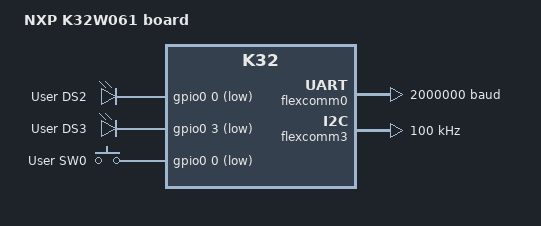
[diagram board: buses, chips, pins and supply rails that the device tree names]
/*
 * Copyright (c) 2021, Vincent van der Locht
 *
 * SPDX-License-Identifier: Apache-2.0
 */

/dts-v1/;

#include <nxp/nxp_k32w061.dtsi>

/ {
	model = "NXP K32W061 board";
	compatible = "nxp,k32w061", "nxp,k32";

	aliases {
		led0 = &red_led_0;
		led1 = &red_led_1;
		sw0 = &user_button;
	};

	chosen {
		zephyr,sram = &sram0;
		zephyr,flash = &flash0;
		zephyr,console = &flexcomm0;
		zephyr,shell-uart = &flexcomm0;
	};

	leds {
		compatible = "gpio-leds";
		red_led_0: led_0 {
			gpios = <&gpio0 0 GPIO_ACTIVE_LOW>;
			label = "User DS2";
		};
		red_led_1: led_1 {
			gpios = <&gpio0 3 GPIO_ACTIVE_LOW>;
			label = "User DS3";
		};
	};

	gpio_keys {
		compatible = "gpio-keys";
		user_button: button_0 {
			label = "User SW0";
			gpios = <&gpio0 0 GPIO_ACTIVE_LOW>;
		};
	};

};

&cpu0 {
	clock-frequency = <48000000>;
};


&flexcomm0 {
    compatible = "nxp,lpc-usart";
	/* current-speed = <115200>; */
    current-speed = <2000000>;
	status = "okay";
};

&flexcomm1 {
    compatible = "nxp,lpc-usart";
	current-speed = <115200>;
	status = "disabled";
};

&flexcomm2 {
    compatible = "nxp,lpc-i2c";
    clock-frequency = <I2C_BITRATE_STANDARD>;
	#address-cells = <1>;
	#size-cells = <0>;
	status = "disabled";
};

&flexcomm3 {
    compatible = "nxp,lpc-i2c";
    clock-frequency = <I2C_BITRATE_STANDARD>;
	#address-cells = <1>;
	#size-cells = <0>;
	status = "okay";
};

&flexcomm4 {
    compatible = "nxp,lpc-spi";
	status = "disabled";
    #address-cells = <1>;
	#size-cells = <0>;
};

&flexcomm5 {
    compatible = "nxp,lpc-spi";
	status = "disabled";
    #address-cells = <1>;
	#size-cells = <0>;
};

&flexcomm6 {
    compatible = "nxp,lpc-i2c";
    clock-frequency = <I2C_BITRATE_STANDARD>;
	#address-cells = <1>;
	#size-cells = <0>;
	status = "disabled";
};

&gpio0 {
	status = "okay";
};
